# COMPUTE_CLUSTER0_CLEC_REGS register map
Vendor: Texas Instruments
Peripheral module from a debugger description file (folder J7ES).
Registers are 32-bit, read-only, reset values left out (the file's numbers can be read two ways) unless marked. A register's access mark holds for its fields unless they carry their own. Offsets are as the file gives them; lines under a group give offsets from that group; [hi:lo] are bit positions; {n}, {i} and the like mark numbered series; 'fields as' and 'values as' point back to an identical list; <NAME> marks a mode.

## COMPUTE_CLUSTER0_CLEC_REGS
0x00 CLEC_PID — Peripheral identification register. Uniquely identifies the module and its specific revision.
  [31:0] REV — TI internal data. Identifies revision of peripheral.
0xA000 CLEC_EFR_k — Event flag register. This is a read-only register which contains pending flag for all events queued by CLEC. This flag is set regardless if corresponding event is enabled or disabled. Offset = A000h + (k * 4h); where k = 0h to 3Eh.
  [31:0] EVNTFR — Event pending flags for events 0 to N. For pulse events, an event flag is cleared as soon as corresponding event is sent. For level events, an event flag is cleared when corresponding interrupt event is deasserted. This is to support scenario where CPU wants to disable some event temporarily, while doing some important task, and then re-enable the event; however, when CPU re-enables the event, CPU does not want to miss any event that occurred when it was disabled temporarily.
0xB000 CLEC_EDR_k — Event drop register. This is a read-only register which contains dropped event flag for each event. For input events which are pulse and not level, if CLEC receives back to back pulses of event and second pulse comes before event flag for the first event is cleared (which means event is not sent from CLEC queue yet), there is no way to tell destination that there were two events requested. CLEC will generate dropped event interrupt in this case and will also set corresponding event dropped flag in register. Offset = B000h + (k * 4h); where k = 0h to 3Eh.
  [31:0] EVNTFR — Dropped event flags for events 0 to N. This flag bit is set until SW clears it by writing 0x2 to the corresponding
0xC000 CLEC_GELRS access per field — Global event lock register for secure claims. The purpose of this register is to allow a hypervisor to expose an event to a virtual machine container, while preventing that virtual machine from changing the configuration. The hypervisor must provide a writeable page to the contained virtual machine so that the virtual machine can use the register. The register acts as a global control, removing write permission to when [31] S = 1. Since only root supervisor has access to the global registers, only root supervisor may change the value of the [0] LOCK bit.
  [0] LOCK rw — Global event lock bit for secure claims. When set, all the event configurations that are marked with
0xD000 CLEC_GELRNS access per field — Global event lock register for non-secure claims. The purpose of this register is to allow a hypervisor to expose an event to a virtual machine container, while preventing that virtual machine from changing the configuration. The hypervisor must provide a writeable page to the contained virtual machine so that the virtual machine can use the register. The register acts as a global control, removing write permission to when [31] S = 0. Since only root supervisor has access to the global registers, only root supervisor may change the value of the [0] LOCK bit.
  fields as CLEC_GELRS
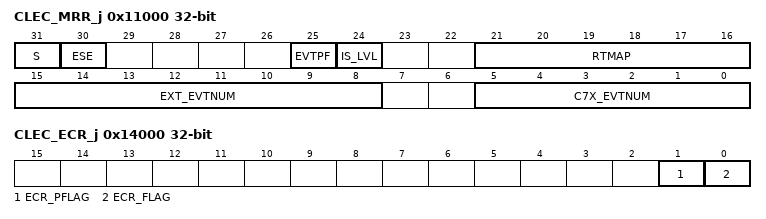
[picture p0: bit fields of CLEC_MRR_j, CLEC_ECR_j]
0x11000 CLEC_MRR_j access per field — Map and routing register. This register is readable by any privilege level. It is writeable by supervisor mode if unlocked by or registers. Offset = 11000h + (j * 00010000h); where j = 0h to 7FEh.
  [31] S rw — Secure claim. If set to 1, a non-secure read/write to
  [30] ESE rw — Event send enable. Controls whether CLEC sends this event when
  [25] EVTPF ro — Event pending flag. Same value as corresponding
  [24] IS_LVL rw — Indicates if input event is level (1) or pulse (0). It is expected from firmware to initialize this information accurately for proper CLEC operation
  [21:16] RTMAP rw — Routing table map.Bit [16] controls the disable/enable of the event routing. Bit [16] = 1 disables the event routing (that is, the event is not send anywhere), regardless of the configuration of the [21-17] bits. Bit [16] = 0 allows sending the event to any supported destination depending on the configuration of the [21-17] bits. . Bit [17] controls the export of the event out of the Compute Cluster to the system (SoC). If bit [17] = 1 AND bit [16] = 0, the event is routed to the system. . Bits [21-18] controls the routing of the event to any Compute Cluster internal CPU corepac (Arm or DSP), as long as bit [16] = 0. The encoding of the [21-18] bits is generic and the actual available options depend on SoC integration. The encoding is as follows: . Note: For events mapped to DRU or Arm Corepac (via the [15-8] EXT_EVTNUM bit field), RTMAP is 'don’t care'. .
  [15:8] EXT_EVTNUM rw — Encoded external event number to send when this event is triggered
  [5:0] C7X_EVTNUM rw — C7x event number to send when this event is triggered
0x13000 CLEC_ESR_j wo — Event send register. This is a write-only register. It ignores the value written (stateless). When written, the CLEC will: Otherwise, the CLEC does not send an event in response to the write; instead, it returns a privilege error for the write status. Corepac powerup/powerdown sequence should comprehend CLEC sequencing to avoid interrupt dropped events. Offset = 13000h + (j * 00010000h); where j = 0h to 7FEh.
0x14000 CLEC_ECR_j wo — Event clear register. This is a write-only register. When written value 0x1, the CLEC will clear any level interrupt set for that event. Offset = 14000h + (j * 00010000h); where j = 0h to 7FEh
  [1] ECR_PFLAG — Writing 1 to this bit clears associated
  [0] ECR_FLAG — Writing 1 to this bit clears event and associated
